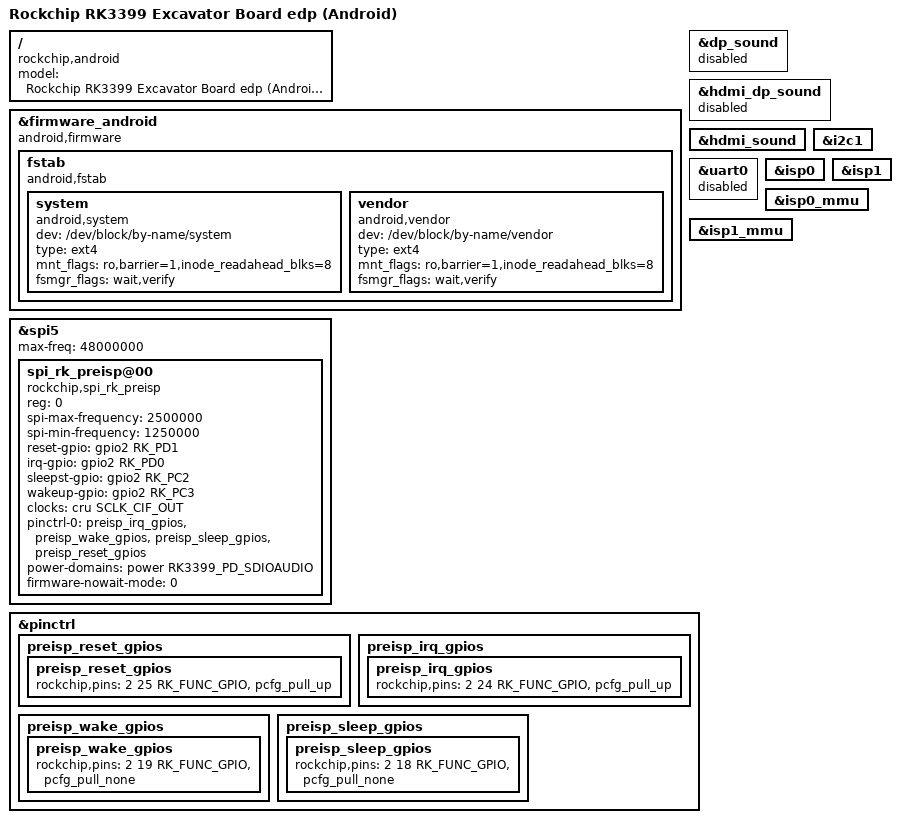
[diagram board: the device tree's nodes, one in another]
/*
 * Copyright (c) 2016 Fuzhou Rockchip Electronics Co., Ltd
 *
 * This file is dual-licensed: you can use it either under the terms
 * of the GPL or the X11 license, at your option. Note that this dual
 * licensing only applies to this file, and not this project as a
 * whole.
 *
 *  a) This file is free software; you can redistribute it and/or
 *     modify it under the terms of the GNU General Public License as
 *     published by the Free Software Foundation; either version 2 of the
 *     License, or (at your option) any later version.
 *
 *     This file is distributed in the hope that it will be useful,
 *     but WITHOUT ANY WARRANTY; without even the implied warranty of
 *     MERCHANTABILITY or FITNESS FOR A PARTICULAR PURPOSE.  See the
 *     GNU General Public License for more details.
 *
 * Or, alternatively,
 *
 *  b) Permission is hereby granted, free of charge, to any person
 *     obtaining a copy of this software and associated documentation
 *     files (the "Software"), to deal in the Software without
 *     restriction, including without limitation the rights to use,
 *     copy, modify, merge, publish, distribute, sublicense, and/or
 *     sell copies of the Software, and to permit persons to whom the
 *     Software is furnished to do so, subject to the following
 *     conditions:
 *
 *     The above copyright notice and this permission notice shall be
 *     included in all copies or substantial portions of the Software.
 *
 *     THE SOFTWARE IS PROVIDED "AS IS", WITHOUT WARRANTY OF ANY KIND,
 *     EXPRESS OR IMPLIED, INCLUDING BUT NOT LIMITED TO THE WARRANTIES
 *     OF MERCHANTABILITY, FITNESS FOR A PARTICULAR PURPOSE AND
 *     NONINFRINGEMENT. IN NO EVENT SHALL THE AUTHORS OR COPYRIGHT
 *     HOLDERS BE LIABLE FOR ANY CLAIM, DAMAGES OR OTHER LIABILITY,
 *     WHETHER IN AN ACTION OF CONTRACT, TORT OR OTHERWISE, ARISING
 *     FROM, OUT OF OR IN CONNECTION WITH THE SOFTWARE OR THE USE OR
 *     OTHER DEALINGS IN THE SOFTWARE.
 */

/dts-v1/;
#include "rk3399-sapphire-excavator-edp.dtsi"

/ {
	model = "Rockchip RK3399 Excavator Board edp (Android)";
	compatible = "rockchip,android", "rockchip,rk3399-excavator-edp", "rockchip,rk3399";
};

&firmware_android {
	compatible = "android,firmware";
	fstab {
		compatible = "android,fstab";
		system {
			compatible = "android,system";
			dev = "/dev/block/by-name/system";
			type = "ext4";
			mnt_flags = "ro,barrier=1,inode_readahead_blks=8";
			fsmgr_flags = "wait,verify";
		};
		vendor {
			compatible = "android,vendor";
			dev = "/dev/block/by-name/vendor";
			type = "ext4";
			mnt_flags = "ro,barrier=1,inode_readahead_blks=8";
			fsmgr_flags = "wait,verify";
		};
	};
};

&dp_sound {
	status = "disabled";
};

&hdmi_dp_sound {
	status = "disabled";
};

&hdmi_sound {
	status = "okay";
};

&i2c1 {
	status = "okay";
};

&uart0 {
	status = "disabled";
};

&isp0 {
	status = "okay";
};

&isp1 {
	status = "okay";
};

&isp0_mmu {
	status = "okay";
};

&isp1_mmu {
	status = "okay";
};

&spi5 {
	status = "okay";
	max-freq = <48000000>;
	spi_rk_preisp@00 {
		compatible =  "rockchip,spi_rk_preisp";
		status = "okay";
		reg = <0>;
		spi-max-frequency = <2500000>;
		spi-min-frequency = <1250000>;
		reset-gpio = <&gpio2 RK_PD1 GPIO_ACTIVE_HIGH>;
		irq-gpio = <&gpio2 RK_PD0 GPIO_ACTIVE_HIGH>;
		sleepst-gpio = <&gpio2 RK_PC2 GPIO_ACTIVE_HIGH>;
		wakeup-gpio = <&gpio2 RK_PC3 GPIO_ACTIVE_HIGH>;
		clocks = <&cru SCLK_CIF_OUT>;
		clock-names = "mclk";
		pinctrl-names = "default";
		pinctrl-0 = <&preisp_irq_gpios &preisp_wake_gpios &preisp_sleep_gpios &preisp_reset_gpios>;
		power-domains = <&power RK3399_PD_SDIOAUDIO>;
		firmware-nowait-mode = <0>;
    };
};

&pinctrl {
	preisp_reset_gpios {
		preisp_reset_gpios: preisp_reset_gpios {
				rockchip,pins = <2 25 RK_FUNC_GPIO &pcfg_pull_up>;
		};
	};

	preisp_irq_gpios {
		preisp_irq_gpios: preisp_irq_gpios {
				rockchip,pins = <2 24 RK_FUNC_GPIO &pcfg_pull_up>;
		};
	};

	preisp_wake_gpios {
		preisp_wake_gpios: preisp_wake_gpios {
				rockchip,pins = <2 19 RK_FUNC_GPIO &pcfg_pull_none>;
		};
	};

	preisp_sleep_gpios {
		preisp_sleep_gpios: preisp_sleep_gpios {
				rockchip,pins = <2 18 RK_FUNC_GPIO &pcfg_pull_none>;
		};
	};
};
